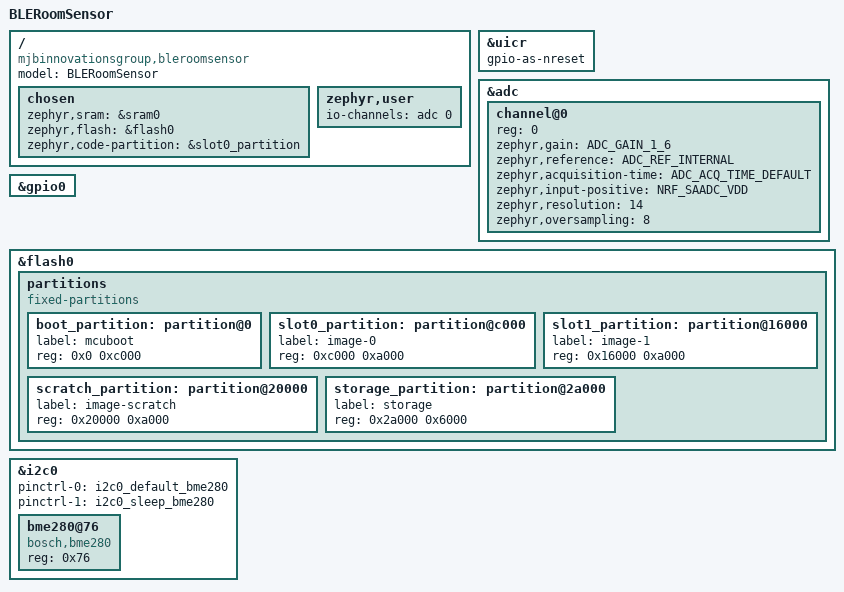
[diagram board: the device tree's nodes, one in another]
// Copyright (c) 2024 Nordic Semiconductor ASA
// SPDX-License-Identifier: Apache-2.0

/dts-v1/;
#include <nordic/nrf52811_qfaa.dtsi>
#include "bleroomsensor-pinctrl.dtsi"


/ {
	model = "BLERoomSensor";
	compatible = "mjbinnovationsgroup,bleroomsensor";

	chosen {
		zephyr,sram = &sram0;
		zephyr,flash = &flash0;
		zephyr,code-partition = &slot0_partition;
	};

  zephyr,user {
    io-channels = <&adc 0>;
  };
};

&uicr {
  gpio-as-nreset;
};


&adc {
	status = "okay";
  #address-cells = <1>;
	#size-cells = <0>;

  channel@0 {
		reg = <0>;
		zephyr,gain = "ADC_GAIN_1_6";
		zephyr,reference = "ADC_REF_INTERNAL";
		zephyr,acquisition-time = <ADC_ACQ_TIME_DEFAULT>;
		zephyr,input-positive = <NRF_SAADC_VDD>;
		zephyr,resolution = <14>;
		zephyr,oversampling = <8>;
	};

};

&gpio0 {
	status = "okay";
};

&flash0 {
	partitions {
		compatible = "fixed-partitions";
		#address-cells = <1>;
		#size-cells = <1>;

		boot_partition: partition@0 {
			label = "mcuboot";
			reg = <0x0 0xc000>;
		};
		slot0_partition: partition@c000 {
			label = "image-0";
			reg = <0xc000 0xa000>;
		};
		slot1_partition: partition@16000 {
			label = "image-1";
			reg = <0x16000 0xa000>;
		};
		scratch_partition: partition@20000 {
			label = "image-scratch";
			reg = <0x20000 0xa000>;
		};
		storage_partition: partition@2a000 {
			label = "storage";
			reg = <0x2a000 0x6000>;
		};
	};
};

&i2c0 {
  status="okay";
  pinctrl-0 = <&i2c0_default_bme280>;
	pinctrl-1 = <&i2c0_sleep_bme280>;
	pinctrl-names = "default", "sleep";

  bme280@76 {
    compatible = "bosch,bme280";
    reg = <0x76>;
  };
};
